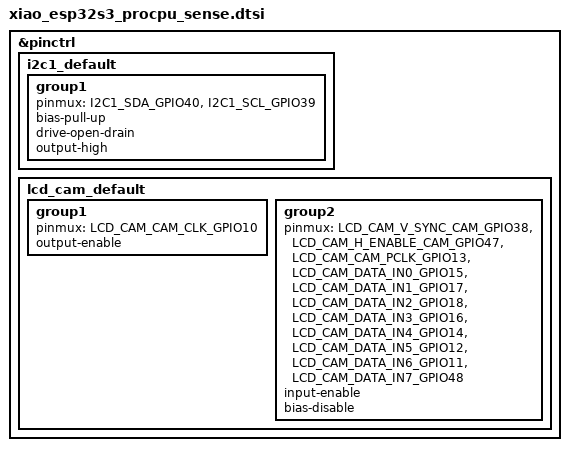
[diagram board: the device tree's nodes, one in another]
/*
 * Copyright 2022 Google LLC
 *
 * SPDX-License-Identifier: Apache-2.0
 */

&pinctrl {
	i2c1_default: i2c1_default {
		group1 {
			pinmux = <I2C1_SDA_GPIO40>,
				 <I2C1_SCL_GPIO39>;
			bias-pull-up;
			drive-open-drain;
			output-high;
		};
	};

	lcd_cam_default: lcd_cam_default {
		group1 {
			pinmux = <LCD_CAM_CAM_CLK_GPIO10>;
			output-enable;
		};
		group2 {
			pinmux = <LCD_CAM_V_SYNC_CAM_GPIO38>,
				<LCD_CAM_H_ENABLE_CAM_GPIO47>,
				<LCD_CAM_CAM_PCLK_GPIO13>,
				<LCD_CAM_DATA_IN0_GPIO15>,
				<LCD_CAM_DATA_IN1_GPIO17>,
				<LCD_CAM_DATA_IN2_GPIO18>,
				<LCD_CAM_DATA_IN3_GPIO16>,
				<LCD_CAM_DATA_IN4_GPIO14>,
				<LCD_CAM_DATA_IN5_GPIO12>,
				<LCD_CAM_DATA_IN6_GPIO11>,
				<LCD_CAM_DATA_IN7_GPIO48>;
			input-enable;
			bias-disable;
		};
	};
};
